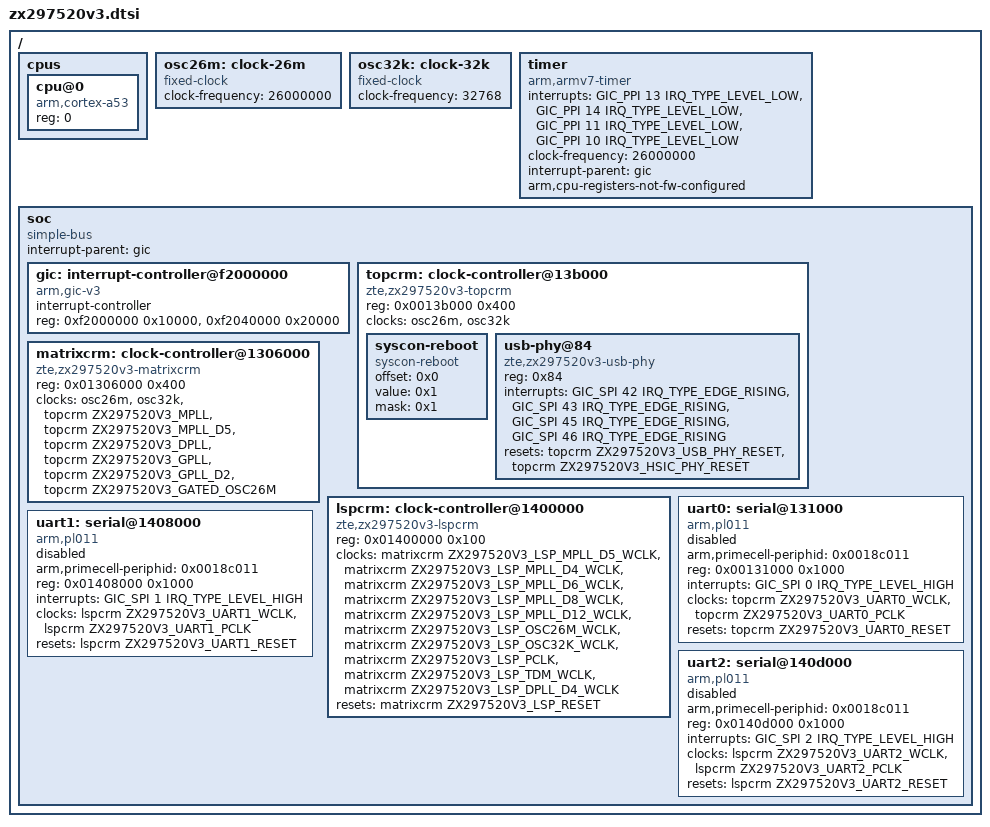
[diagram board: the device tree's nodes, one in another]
// SPDX-License-Identifier: GPL-2.0-only
/*
 * Copyright (c) 2026 Stefan Dösinger <stefandoesinger@gmail.com>
 */

#include <dt-bindings/interrupt-controller/arm-gic.h>
#include <dt-bindings/reset/zte,zx297520v3-reset.h>
#include <dt-bindings/clock/zte,zx297520v3-clk.h>

/ {
	#address-cells = <1>;
	#size-cells = <1>;

	cpus {
		#address-cells = <1>;
		#size-cells = <0>;

		cpu@0 {
			device_type = "cpu";
			compatible = "arm,cortex-a53";
			reg = <0>;
		};
	};

	osc26m: clock-26m {
		compatible = "fixed-clock";
		clock-frequency = <26000000>;
		#clock-cells = <0>;
	};

	osc32k: clock-32k {
		compatible = "fixed-clock";
		clock-frequency = <32768>;
		#clock-cells = <0>;
	};

	timer {
		compatible = "arm,armv7-timer";
		interrupts = <GIC_PPI 13 IRQ_TYPE_LEVEL_LOW>,
			     <GIC_PPI 14 IRQ_TYPE_LEVEL_LOW>,
			     <GIC_PPI 11 IRQ_TYPE_LEVEL_LOW>,
			     <GIC_PPI 10 IRQ_TYPE_LEVEL_LOW>;
		clock-frequency = <26000000>;
		interrupt-parent = <&gic>;
		/* I don't think uboot sets CNTVOFF and the stock kernel doesn't use the
		 * arm timer at all. Since this is a single CPU system I don't think it
		 * really matters that the offset is random though.
		 */
		arm,cpu-registers-not-fw-configured;
	};

	soc {
		#address-cells = <1>;
		#size-cells = <1>;
		compatible = "simple-bus";
		interrupt-parent = <&gic>;
		ranges;

		/* The GIC has a non-standard way of configuring ints between level-low/level
		 * high or rising edge/falling edge at 0xf2202070 and onwards. See AP_INT_MODE_BASE
		 * and AP_PPI_MODE_REG in the ZTE kernel, although the offsets in the kernel source
		 * seem wrong.
		 *
		 * Everything defaults to active-high/rising edge, but the timer is active-low. We
		 * currently rely on the boot loader to change timer IRQs to active-low for us for
		 * now.
		 */
		gic: interrupt-controller@f2000000 {
			compatible = "arm,gic-v3";
			interrupt-controller;
			#interrupt-cells = <3>;
			#address-cells = <1>;
			#size-cells = <1>;
			reg = <0xf2000000 0x10000>,
			      <0xf2040000 0x20000>;
		};

		topcrm: clock-controller@13b000 {
			compatible = "zte,zx297520v3-topcrm", "syscon";
			reg = <0x0013b000 0x400>;
			#address-cells = <1>;
			#size-cells = <0>;
			#clock-cells = <1>;
			#reset-cells = <1>;
			clocks = <&osc26m>, <&osc32k>;
			clock-names = "osc26m", "osc32k";

			syscon-reboot {
				compatible = "syscon-reboot";
				offset = <0x0>;
				value = <0x1>;
				mask = <0x1>;
			};

			usb-phy@84 {
				compatible = "zte,zx297520v3-usb-phy";
				reg = <0x84>;
				interrupts = <GIC_SPI 42 IRQ_TYPE_EDGE_RISING>,
					     <GIC_SPI 43 IRQ_TYPE_EDGE_RISING>,
					     <GIC_SPI 45 IRQ_TYPE_EDGE_RISING>,
					     <GIC_SPI 46 IRQ_TYPE_EDGE_RISING>;
				interrupt-names = "usb-up", "usb-down", "hsic-up", "hsic-down";
				resets = <&topcrm ZX297520V3_USB_PHY_RESET>,
					 <&topcrm ZX297520V3_HSIC_PHY_RESET>;
				reset-names = "usb", "hsic";
				#phy-cells = <1>;
			};
		};

		matrixcrm: clock-controller@1306000 {
			compatible = "zte,zx297520v3-matrixcrm";
			reg = <0x01306000 0x400>;
			clocks = <&osc26m>, <&osc32k>,
				 <&topcrm ZX297520V3_MPLL>, <&topcrm ZX297520V3_MPLL_D5>,
				 <&topcrm ZX297520V3_DPLL>, <&topcrm ZX297520V3_GPLL>,
				 <&topcrm ZX297520V3_GPLL_D2>, <&topcrm ZX297520V3_GATED_OSC26M>;
			clock-names = "osc26m", "osc32k", "mpll", "mpll-d5", "dpll",
				"gpll", "gpll-d2", "wclk-osc26m";
			#clock-cells = <1>;
			#hwlock-cells = <1>;
			#reset-cells = <1>;
		};

		lspcrm: clock-controller@1400000 {
			compatible = "zte,zx297520v3-lspcrm";
			reg = <0x01400000 0x100>;
			#clock-cells = <1>;
			#reset-cells = <1>;

			clocks = <&matrixcrm ZX297520V3_LSP_MPLL_D5_WCLK>,
				 <&matrixcrm ZX297520V3_LSP_MPLL_D4_WCLK>,
				 <&matrixcrm ZX297520V3_LSP_MPLL_D6_WCLK>,
				 <&matrixcrm ZX297520V3_LSP_MPLL_D8_WCLK>,
				 <&matrixcrm ZX297520V3_LSP_MPLL_D12_WCLK>,
				 <&matrixcrm ZX297520V3_LSP_OSC26M_WCLK>,
				 <&matrixcrm ZX297520V3_LSP_OSC32K_WCLK>,
				 <&matrixcrm ZX297520V3_LSP_PCLK>,
				 <&matrixcrm ZX297520V3_LSP_TDM_WCLK>,
				 <&matrixcrm ZX297520V3_LSP_DPLL_D4_WCLK>;
			clock-names = "mpll-d5", "mpll-d4", "mpll-d6", "mpll-d8", "mpll-d12",
				      "osc26m", "osc32k", "pclk", "tdm-wclk", "dpll-d4";
			resets = <&matrixcrm ZX297520V3_LSP_RESET>;
		};


		uart0: serial@131000 {
			compatible = "arm,pl011", "arm,primecell";
			arm,primecell-periphid = <0x0018c011>;
			reg = <0x00131000 0x1000>;
			interrupts = <GIC_SPI 0 IRQ_TYPE_LEVEL_HIGH>;
			clocks = <&topcrm ZX297520V3_UART0_WCLK>, <&topcrm ZX297520V3_UART0_PCLK>;
			clock-names = "uartclk", "apb_pclk";
			resets = <&topcrm ZX297520V3_UART0_RESET>;
			status = "disabled";
		};

		uart1: serial@1408000 {
			compatible = "arm,pl011", "arm,primecell";
			arm,primecell-periphid = <0x0018c011>;
			reg = <0x01408000 0x1000>;
			interrupts = <GIC_SPI 1 IRQ_TYPE_LEVEL_HIGH>;
			clocks = <&lspcrm ZX297520V3_UART1_WCLK>, <&lspcrm ZX297520V3_UART1_PCLK>;
			clock-names = "uartclk", "apb_pclk";
			resets = <&lspcrm ZX297520V3_UART1_RESET>;
			status = "disabled";
		};

		uart2: serial@140d000 {
			compatible = "arm,pl011", "arm,primecell";
			arm,primecell-periphid = <0x0018c011>;
			reg = <0x0140d000 0x1000>;
			interrupts = <GIC_SPI 2 IRQ_TYPE_LEVEL_HIGH>;
			clocks = <&lspcrm ZX297520V3_UART2_WCLK>, <&lspcrm ZX297520V3_UART2_PCLK>;
			clock-names = "uartclk", "apb_pclk";
			resets = <&lspcrm ZX297520V3_UART2_RESET>;
			status = "disabled";
		};
	};
};
